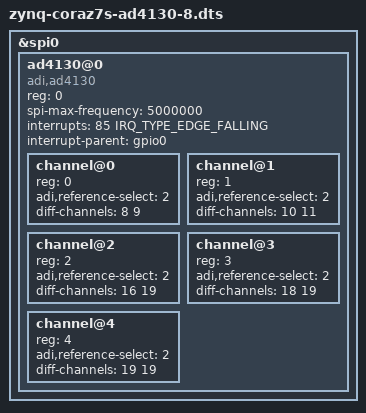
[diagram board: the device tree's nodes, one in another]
// SPDX-License-Identifier: GPL-2.0-or-later
/*
 * Analog Devices AD4130-8
 * https://www.analog.com/en/products/ad4130-8.html
 *
 * hdl_project: <ad719x_asdz/coraz7s>
 *
 * Copyright (C) 2026 Analog Devices, Inc.
 */
/dts-v1/;
#include "zynq-coraz7s.dtsi"
#include <dt-bindings/gpio/gpio.h>
#include <dt-bindings/interrupt-controller/irq.h>

&spi0 {
	status = "okay";

	ad4130@0 {
		compatible = "adi,ad4130";
		reg = <0>;

		#address-cells = <1>;
		#size-cells = <0>;

		spi-max-frequency = <5000000>;
		interrupts = <85 IRQ_TYPE_EDGE_FALLING>;
		interrupt-parent = <&gpio0>;

		channel@0 {
			reg = <0>;

			adi,reference-select = <2>;

			/* AIN8, AIN9 */
			diff-channels = <8 9>;
		};

		channel@1 {
			reg = <1>;

			adi,reference-select = <2>;

			/* AIN10, AIN11 */
			diff-channels = <10 11>;
		};

		channel@2 {
			reg = <2>;

			adi,reference-select = <2>;

			/* Temperature Sensor, DGND */
			diff-channels = <16 19>;
		};

		channel@3 {
			reg = <3>;

			adi,reference-select = <2>;

			/* Internal reference, DGND */
			diff-channels = <18 19>;
		};

		channel@4 {
			reg = <4>;

			adi,reference-select = <2>;

			/* DGND, DGND */
			diff-channels = <19 19>;
		};
	};
};
